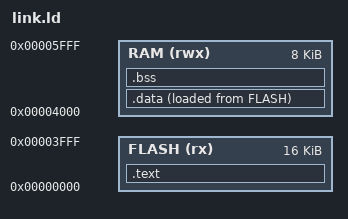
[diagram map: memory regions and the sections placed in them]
ENTRY(_start)

MEMORY
{
    FLASH (rx)  : ORIGIN = 0x00000000, LENGTH = 16K
    RAM   (rwx) : ORIGIN = 0x00004000, LENGTH = 8K
}

SECTIONS
{
    .text : {
        KEEP(*(.text.start))
        *(.text .text.*)
        *(.rodata .rodata.*)
    } > FLASH

    .data : {
        *(.data .data.*)
    } > RAM AT > FLASH

    .bss (NOLOAD) : {
        *(.bss .bss.*)
        *(COMMON)
    } > RAM

    _stack_top = ORIGIN(RAM) + LENGTH(RAM);
}
